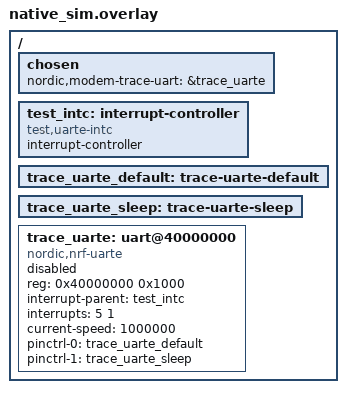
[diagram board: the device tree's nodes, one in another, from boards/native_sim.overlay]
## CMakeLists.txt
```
#
# Copyright (c) 2026 Nordic Semiconductor ASA
#
# SPDX-License-Identifier: LicenseRef-Nordic-5-Clause
#

cmake_minimum_required(VERSION 3.20.0)

find_package(Zephyr REQUIRED HINTS $ENV{ZEPHYR_BASE})
project(uart_nrfx)

zephyr_get(TEST_BOUNCE_BUF_SZ)
if(NOT DEFINED TEST_BOUNCE_BUF_SZ)
  set(TEST_BOUNCE_BUF_SZ 8)
endif()

# Stub headers for nrfx, pinctrl and DMM. They take precedence over the Zephyr headers.
target_include_directories(app BEFORE PRIVATE stubs)
target_include_directories(app PRIVATE src)
target_include_directories(app PRIVATE ${ZEPHYR_NRF_MODULE_DIR}/include/modem/)

# Provide compile-time definitions for configs expected by the backend
target_compile_definitions(app PRIVATE
  CONFIG_NRF_MODEM_LIB_TRACE_BACKEND_UART_NRFX_CHUNK_SZ=16
  CONFIG_NRF_MODEM_LIB_TRACE_BACKEND_UART_NRFX_BOUNCE_BUF_SZ=${TEST_BOUNCE_BUF_SZ}
  CONFIG_NRF_MODEM_LIB_TRACE_BACKEND_UART_NRFX_TX_TIMEOUT_MS=20
)

# Generate runner for the test
test_runner_generate(src/main.c)

target_sources(app PRIVATE
  src/main.c
  src/fake_nrfx_uarte.c
)

# Add the unit under test
target_sources(app PRIVATE
  ${ZEPHYR_NRF_MODULE_DIR}/lib/nrf_modem_lib/trace_backends/uart_nrfx/uart_nrfx.c)
```

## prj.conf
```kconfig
#
# Copyright (c) 2026 Nordic Semiconductor ASA
#
# SPDX-License-Identifier: LicenseRef-Nordic-5-Clause
#

CONFIG_UNITY=y
CONFIG_ASSERT=y
```

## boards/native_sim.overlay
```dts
/*
 * Copyright (c) 2026 Nordic Semiconductor ASA
 *
 * SPDX-License-Identifier: LicenseRef-Nordic-5-Clause
 */

/ {
	chosen {
		nordic,modem-trace-uart = &trace_uarte;
	};

	test_intc: interrupt-controller {
		compatible = "test,uarte-intc";
		interrupt-controller;
		#interrupt-cells = <2>;
	};

	trace_uarte_default: trace-uarte-default {};

	trace_uarte_sleep: trace-uarte-sleep {};

	trace_uarte: uart@40000000 {
		compatible = "nordic,nrf-uarte";
		reg = <0x40000000 0x1000>;
		interrupt-parent = <&test_intc>;
		interrupts = <5 1>;
		current-speed = <1000000>;
		pinctrl-0 = <&trace_uarte_default>;
		pinctrl-1 = <&trace_uarte_sleep>;
		pinctrl-names = "default", "sleep";
		status = "reserved";
	};
};
```

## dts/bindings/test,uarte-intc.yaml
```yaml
#
# Copyright (c) 2026 Nordic Semiconductor ASA
#
# SPDX-License-Identifier: LicenseRef-Nordic-5-Clause
#

description: Dummy interrupt controller for the UARTE trace backend unit test

compatible: "test,uarte-intc"

include: [base.yaml, interrupt-controller.yaml]

interrupt-cells:
  - irq
  - priority
```

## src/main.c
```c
/*
 * Copyright (c) 2026 Nordic Semiconductor ASA
 *
 * SPDX-License-Identifier: LicenseRef-Nordic-5-Clause
 */

#include <errno.h>
#include <string.h>
#include <unity.h>
#include <zephyr/kernel.h>
#include <zephyr/drivers/pinctrl.h>

#include <modem/trace_backend.h>

#include "fake_nrfx_uarte.h"

#define CHUNK_SZ      CONFIG_NRF_MODEM_LIB_TRACE_BACKEND_UART_NRFX_CHUNK_SZ
#define BOUNCE_BUF_SZ CONFIG_NRF_MODEM_LIB_TRACE_BACKEND_UART_NRFX_BOUNCE_BUF_SZ

#define MAX_CB_CALLS 32

extern int unity_main(void);

extern struct nrf_modem_lib_trace_backend trace_backend;

static uint8_t trace_data[128];

static struct {
	size_t calls;
	size_t lens[MAX_CB_CALLS];
	size_t total;
	/* Return fail_err on the given 1-based call. */
	size_t fail_at;
	int fail_err;
} processed;

static int processed_cb(size_t len)
{
	size_t call = ++processed.calls;

	if (call <= ARRAY_SIZE(processed.lens)) {
		processed.lens[call - 1] = len;
	}

	if (call == processed.fail_at) {
		return processed.fail_err;
	}

	processed.total += len;

	return 0;
}

static void backend_init(void)
{
	TEST_ASSERT_EQUAL(0, trace_backend.init(processed_cb));
}

/* The trace library deinitializes the backend after a write error. */
static void backend_reinit(void)
{
	TEST_ASSERT_EQUAL(0, trace_backend.deinit());
	backend_init();
}

static void reset_counters(void)
{
	memset(&processed, 0, sizeof(processed));
	fake_uarte.tx_calls = 0;
	fake_uarte.async_aborts = 0;
	fake_uarte.sync_aborts = 0;
	fake_uarte.events = 0;
	fake_uarte.sent_len = 0;
}

static void make_trace_data_inaccessible(void)
{
	fake_uarte.inaccessible = trace_data;
	fake_uarte.inaccessible_len = sizeof(trace_data);
}

/* Assert that a write of len bytes completed fully and in order, in chunks. */
static void assert_write_complete(int ret, size_t len, size_t chunk)
{
	TEST_ASSERT_EQUAL(len, ret);
	TEST_ASSERT_EQUAL(len, processed.total);
	TEST_ASSERT_EQUAL(DIV_ROUND_UP(len, chunk), processed.calls);
	for (size_t i = 0; i < processed.calls; i++) {
		TEST_ASSERT_EQUAL(MIN(chunk, len - i * chunk), processed.lens[i]);
	}
	TEST_ASSERT_EQUAL(len, fake_uarte.sent_len);
	TEST_ASSERT_EQUAL_MEMORY(trace_data, fake_uarte.sent, len);
}

/* Assert that a new write is not affected by leftovers of the previous one. */
static void assert_next_write_clean(void)
{
	int ret;

	fake_uarte.stalled = false;
	fake_uarte.abort_stuck = false;
	fake_uarte.complete_on_sync_abort = false;
	fake_uarte.complete_all = false;
	fake_uarte.tx_fail_at = 0;
	fake_uarte.link_cancel_count = 0;
	reset_counters();

	ret = trace_backend.write(trace_data, CHUNK_SZ + 4);
	assert_write_complete(ret, CHUNK_SZ + 4, CHUNK_SZ);
	TEST_ASSERT_EQUAL(2, fake_uarte.events);
}

void setUp(void)
{
	fake_uarte_reset();
	memset(&processed, 0, sizeof(processed));

	for (size_t i = 0; i < sizeof(trace_data); i++) {
		trace_data[i] = (uint8_t)(i * 7 + 3);
	}
}

void tearDown(void)
{
	(void)trace_backend.deinit();

	TEST_ASSERT_NULL_MESSAGE(fake_uarte.protocol_error, fake_uarte.protocol_error);
	TEST_ASSERT_FALSE(fake_uarte.overwrite_detected);
	TEST_ASSERT_LESS_OR_EQUAL(2, fake_uarte.max_queued);
}

void test_init_null_callback(void)
{
	TEST_ASSERT_EQUAL(-EFAULT, trace_backend.init(NULL));
	TEST_ASSERT_FALSE(fake_uarte.initialized);
}

void test_init_configures_uarte(void)
{
	backend_init();

	TEST_ASSERT_TRUE(fake_uarte.initialized);
	TEST_ASSERT_EQUAL(PINCTRL_STATE_DEFAULT, fake_uarte.pinctrl_state);
	/* 1 Mbaud from a 16 MHz clock: 2^12 * floor(2^20 / 16). */
	TEST_ASSERT_EQUAL_HEX32(0x10000000, fake_uarte.config.baudrate);
	TEST_ASSERT_EQUAL(NRF_UARTE_HWFC_DISABLED, fake_uarte.config.config.hwfc);
	TEST_ASSERT_TRUE(fake_uarte.config.skip_psel_cfg);
	TEST_ASSERT_TRUE(fake_uarte.config.skip_gpio_cfg);
	TEST_ASSERT_EQUAL(1, fake_uarte.config.interrupt_priority);

	/* Initializing again only updates the callback. */
	backend_init();
	TEST_ASSERT_EQUAL(1, fake_uarte.init_calls);
}

void test_init_pinctrl_error(void)
{
	fake_uarte.pinctrl_err = -EIO;

	TEST_ASSERT_EQUAL(-EIO, trace_backend.init(processed_cb));
	TEST_ASSERT_FALSE(fake_uarte.initialized);
	TEST_ASSERT_EQUAL(-EPERM, trace_backend.write(trace_data, 4));
}

void test_write_not_initialized(void)
{
	TEST_ASSERT_EQUAL(-EPERM, trace_backend.write(trace_data, 4));
	TEST_ASSERT_EQUAL(0, fake_uarte.tx_calls);
}

void test_deinit(void)
{
	backend_init();

	TEST_ASSERT_EQUAL(0, trace_backend.deinit());
	TEST_ASSERT_FALSE(fake_uarte.initialized);
	TEST_ASSERT_EQUAL(PINCTRL_STATE_SLEEP, fake_uarte.pinctrl_state);
	TEST_ASSERT_EQUAL(-EPERM, trace_backend.write(trace_data, 4));
}

void test_write_single_chunk(void)
{
	int ret;

	backend_init();

	ret = trace_backend.write(trace_data, 10);

	assert_write_complete(ret, 10, CHUNK_SZ);
	TEST_ASSERT_EQUAL(1, fake_uarte.tx_calls);
	TEST_ASSERT_EQUAL(0, fake_uarte.tx_log[0].flags);
	TEST_ASSERT_EQUAL_PTR(trace_data, fake_uarte.tx_log[0].buf);
}

void test_write_links_chunks(void)
{
	const size_t len = 3 * CHUNK_SZ + 5;
	int ret;

	backend_init();

	ret = trace_backend.write(trace_data, len);

	assert_write_complete(ret, len, CHUNK_SZ);
	TEST_ASSERT_EQUAL(4, fake_uarte.tx_calls);
	TEST_ASSERT_EQUAL(2, fake_uarte.max_queued);
	TEST_ASSERT_EQUAL(0, fake_uarte.tx_log[0].flags);
	for (size_t i = 1; i < fake_uarte.tx_calls; i++) {
		TEST_ASSERT_EQUAL(NRFX_UARTE_TX_LINK, fake_uarte.tx_log[i].flags);
		TEST_ASSERT_EQUAL_PTR(&trace_data[i * CHUNK_SZ], fake_uarte.tx_log[i].buf);
	}
	/* BAUDRATE is restored only when starting, not when linking. */
	TEST_ASSERT_EQUAL(1, fake_uarte.baudrate_restores);
}

void test_write_restores_baudrate_on_each_start(void)
{
	int ret;

	backend_init();
	TEST_ASSERT_EQUAL_HEX32(0, fake_uarte.baudrate);

	ret = trace_backend.write(trace_data, 4);
	assert_write_complete(ret, 4, CHUNK_SZ);

	reset_counters();
	ret = trace_backend.write(trace_data, 4);
	assert_write_complete(ret, 4, CHUNK_SZ);

	TEST_ASSERT_EQUAL(2, fake_uarte.baudrate_restores);
}

void test_write_link_after_transfers_done_starts_new(void)
{
	const size_t len = 5 * CHUNK_SZ;
	int ret;

	backend_init();
	fake_uarte.complete_all = true;

	/* Both transfers are done before the next one is linked, so the driver starts a new
	 * transfer which requires BAUDRATE to be restored.
	 */
	ret = trace_backend.write(trace_data, len);

	assert_write_complete(ret, len, CHUNK_SZ);
	TEST_ASSERT_EQUAL(0, fake_uarte.async_aborts);
	TEST_ASSERT_EQUAL(0, fake_uarte.sync_aborts);
	TEST_ASSERT_EQUAL(3, fake_uarte.baudrate_restores);
}

void test_write_link_canceled_is_fatal(void)
{
	backend_init();
	fake_uarte.link_cancel_count = 1;

	TEST_ASSERT_EQUAL(-ECANCELED, trace_backend.write(trace_data, 3 * CHUNK_SZ));
	TEST_ASSERT_EQUAL(2, fake_uarte.tx_calls);
	TEST_ASSERT_EQUAL(NRFX_UARTE_TX_LINK, fake_uarte.tx_log[1].flags);
	TEST_ASSERT_EQUAL(0, fake_uarte.async_aborts);
	TEST_ASSERT_EQUAL(1, fake_uarte.sync_aborts);
	TEST_ASSERT_EQUAL(0, processed.calls);

	backend_reinit();
	assert_next_write_clean();
}

void test_write_tx_error(void)
{
	backend_init();
	fake_uarte.tx_fail_at = 1;
	fake_uarte.tx_fail_err = -EIO;

	TEST_ASSERT_EQUAL(-EIO, trace_backend.write(trace_data, 2 * CHUNK_SZ));
	TEST_ASSERT_EQUAL(1, fake_uarte.tx_calls);
	TEST_ASSERT_EQUAL(0, processed.calls);
	TEST_ASSERT_EQUAL(0, fake_uarte.async_aborts);

	assert_next_write_clean();
}

void test_write_link_error_aborts_active_transfer(void)
{
	backend_init();
	fake_uarte.tx_fail_at = 2;
	fake_uarte.tx_fail_err = -EIO;

	TEST_ASSERT_EQUAL(-EIO, trace_backend.write(trace_data, 2 * CHUNK_SZ));
	TEST_ASSERT_EQUAL(2, fake_uarte.tx_calls);
	TEST_ASSERT_EQUAL(0, fake_uarte.async_aborts);
	TEST_ASSERT_EQUAL(1, fake_uarte.sync_aborts);
	TEST_ASSERT_EQUAL(0, fake_uarte.events);
	TEST_ASSERT_EQUAL(0, processed.calls);

	backend_reinit();
	assert_next_write_clean();
}

void test_write_processed_cb_error_aborts_linked_transfer(void)
{
	backend_init();
	processed.fail_at = 1;
	processed.fail_err = -ENOMEM;
	fake_uarte.abort_partial_len = 4;

	TEST_ASSERT_EQUAL(-ENOMEM, trace_backend.write(trace_data, 3 * CHUNK_SZ));

	/* The third chunk is never sent, and the aborted second chunk is not processed. */
	TEST_ASSERT_EQUAL(2, fake_uarte.tx_calls);
	TEST_ASSERT_EQUAL(1, fake_uarte.async_aborts);
	TEST_ASSERT_EQUAL(0, fake_uarte.sync_aborts);
	TEST_ASSERT_EQUAL(2, fake_uarte.events);
	TEST_ASSERT_EQUAL(1, processed.calls);
	TEST_ASSERT_EQUAL(CHUNK_SZ + 4, fake_uarte.sent_len);

	assert_next_write_clean();
}

void test_write_processed_cb_error_after_all_transfers_done(void)
{
	backend_init();
	processed.fail_at = 1;
	processed.fail_err = -ENOMEM;
	fake_uarte.complete_all = true;

	/* Both transfers are done when the first completion is handled, so the abort finds no
	 * active transfer and the second completion is already queued.
	 */
	TEST_ASSERT_EQUAL(-ENOMEM, trace_backend.write(trace_data, 2 * CHUNK_SZ));
	TEST_ASSERT_EQUAL(1, fake_uarte.async_aborts);
	TEST_ASSERT_EQUAL(0, fake_uarte.sync_aborts);
	TEST_ASSERT_EQUAL(2, fake_uarte.events);
	TEST_ASSERT_EQUAL(1, processed.calls);

	assert_next_write_clean();
}

void test_write_timeout_partial_abort(void)
{
	int ret;

	backend_init();
	fake_uarte.stalled = true;
	fake_uarte.abort_partial_len = 5;

	ret = trace_backend.write(trace_data, 2 * CHUNK_SZ);

	/* Bytes sent before the abort are processed, the linked transfer reports 0 bytes. */
	TEST_ASSERT_EQUAL(5, ret);
	TEST_ASSERT_EQUAL(1, processed.calls);
	TEST_ASSERT_EQUAL(5, processed.total);
	TEST_ASSERT_EQUAL(2, fake_uarte.events);
	TEST_ASSERT_EQUAL(1, fake_uarte.async_aborts);
	TEST_ASSERT_EQUAL(0, fake_uarte.sync_aborts);
	TEST_ASSERT_EQUAL(5, fake_uarte.sent_len);
	TEST_ASSERT_EQUAL_MEMORY(trace_data, fake_uarte.sent, 5);

	assert_next_write_clean();
}

void test_write_timeout_zero_byte_abort(void)
{
	backend_init();
	fake_uarte.stalled = true;
	fake_uarte.abort_partial_len = 0;

	TEST_ASSERT_EQUAL(-EAGAIN, trace_backend.write(trace_data, 2 * CHUNK_SZ));
	TEST_ASSERT_EQUAL(0, processed.calls);
	TEST_ASSERT_EQUAL(2, fake_uarte.events);
	TEST_ASSERT_EQUAL(1, fake_uarte.async_aborts);
	TEST_ASSERT_EQUAL(0, fake_uarte.sync_aborts);

	assert_next_write_clean();
}

void test_write_timeout_escalates_to_sync_abort(void)
{
	backend_init();
	fake_uarte.stalled = true;
	fake_uarte.abort_stuck = true;

	TEST_ASSERT_EQUAL(-ETIMEDOUT, trace_backend.write(trace_data, 2 * CHUNK_SZ));
	TEST_ASSERT_EQUAL(0, processed.calls);
	TEST_ASSERT_EQUAL(0, fake_uarte.events);
	TEST_ASSERT_EQUAL(1, fake_uarte.async_aborts);
	TEST_ASSERT_EQUAL(1, fake_uarte.sync_aborts);

	backend_reinit();
	assert_next_write_clean();
}

void test_write_sync_abort_discards_late_completion(void)
{
	backend_init();
	fake_uarte.stalled = true;
	fake_uarte.abort_stuck = true;
	fake_uarte.complete_on_sync_abort = true;

	/* A completion that races with the synchronous abort is discarded with the write. */
	TEST_ASSERT_EQUAL(-ETIMEDOUT, trace_backend.write(trace_data, 2 * CHUNK_SZ));
	TEST_ASSERT_EQUAL(0, processed.calls);
	TEST_ASSERT_EQUAL(1, fake_uarte.events);
	TEST_ASSERT_EQUAL(1, fake_uarte.sync_aborts);

	backend_reinit();
	assert_next_write_clean();
}

void test_suspend_resume(void)
{
	int ret;

	backend_init();

	TEST_ASSERT_EQUAL(0, trace_backend.suspend());
	TEST_ASSERT_EQUAL(PINCTRL_STATE_SLEEP, fake_uarte.pinctrl_state);
	TEST_ASSERT_EQUAL(-EPERM, trace_backend.write(trace_data, 4));
	TEST_ASSERT_EQUAL(0, fake_uarte.tx_calls);

	TEST_ASSERT_EQUAL(0, trace_backend.resume());
	TEST_ASSERT_EQUAL(PINCTRL_STATE_DEFAULT, fake_uarte.pinctrl_state);

	ret = trace_backend.write(trace_data, 4);
	assert_write_complete(ret, 4, CHUNK_SZ);
}

void test_suspend_pinctrl_error(void)
{
	int ret;

	backend_init();
	fake_uarte.pinctrl_err = -EIO;

	TEST_ASSERT_EQUAL(-EIO, trace_backend.suspend());

	/* The backend is not suspended. */
	fake_uarte.pinctrl_err = 0;
	ret = trace_backend.write(trace_data, 4);
	assert_write_complete(ret, 4, CHUNK_SZ);
}

void test_write_dma_accessible_data_sent_in_place(void)
{
#if BOUNCE_BUF_SZ > 0
	int ret;

	backend_init();

	ret = trace_backend.write(trace_data, 2 * CHUNK_SZ);

	assert_write_complete(ret, 2 * CHUNK_SZ, CHUNK_SZ);
	TEST_ASSERT_EQUAL_PTR(&trace_data[0], fake_uarte.tx_log[0].buf);
	TEST_ASSERT_EQUAL_PTR(&trace_data[CHUNK_SZ], fake_uarte.tx_log[1].buf);
#else
	TEST_IGNORE_MESSAGE("Bounce buffers are disabled");
#endif
}

void test_write_bounce_buffers_alternate(void)
{
#if BOUNCE_BUF_SZ > 0
	const size_t len = 5 * BOUNCE_BUF_SZ;
	int ret;

	backend_init();
	make_trace_data_inaccessible();

	ret = trace_backend.write(trace_data, len);

	assert_write_complete(ret, len, BOUNCE_BUF_SZ);
	TEST_ASSERT_EQUAL(5, fake_uarte.tx_calls);
	TEST_ASSERT_EQUAL(2, fake_uarte.max_queued);
	for (size_t i = 0; i < fake_uarte.tx_calls; i++) {
		TEST_ASSERT_EQUAL(BOUNCE_BUF_SZ, fake_uarte.tx_log[i].len);
		TEST_ASSERT_TRUE(nrf_dma_accessible_check(NULL, fake_uarte.tx_log[i].buf));
	}
	/* Consecutive transfers, which may be in flight at the same time, use different
	 * bounce buffers.
	 */
	for (size_t i = 1; i < fake_uarte.tx_calls; i++) {
		TEST_ASSERT_TRUE(fake_uarte.tx_log[i - 1].buf != fake_uarte.tx_log[i].buf);
	}
	TEST_ASSERT_EQUAL_PTR(fake_uarte.tx_log[0].buf, fake_uarte.tx_log[2].buf);
#else
	TEST_IGNORE_MESSAGE("Bounce buffers are disabled");
#endif
}

void test_write_bounce_buffers_after_abort(void)
{
#if BOUNCE_BUF_SZ > 0
	int ret;

	backend_init();
	make_trace_data_inaccessible();
	fake_uarte.stalled = true;
	fake_uarte.abort_stuck = true;

	TEST_ASSERT_EQUAL(-ETIMEDOUT, trace_backend.write(trace_data, 2 * BOUNCE_BUF_SZ));
	TEST_ASSERT_EQUAL(1, fake_uarte.sync_aborts);

	fake_uarte.stalled = false;
	fake_uarte.abort_stuck = false;
	backend_reinit();
	reset_counters();

	ret = trace_backend.write(trace_data, 3 * BOUNCE_BUF_SZ);
	assert_write_complete(ret, 3 * BOUNCE_BUF_SZ, BOUNCE_BUF_SZ);
#else
	TEST_IGNORE_MESSAGE("Bounce buffers are disabled");
#endif
}

void test_write_not_dma_accessible(void)
{
#if BOUNCE_BUF_SZ == 0
	backend_init();
	make_trace_data_inaccessible();

	TEST_ASSERT_EQUAL(-EFAULT, trace_backend.write(trace_data, CHUNK_SZ));
	TEST_ASSERT_EQUAL(0, fake_uarte.tx_calls);
	TEST_ASSERT_EQUAL(0, processed.calls);
#else
	TEST_IGNORE_MESSAGE("Bounce buffers are enabled");
#endif
}

int main(void)
{
	(void)unity_main();
	return 0;
}
```

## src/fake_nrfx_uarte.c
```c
/*
 * Copyright (c) 2026 Nordic Semiconductor ASA
 *
 * SPDX-License-Identifier: LicenseRef-Nordic-5-Clause
 */

#include <errno.h>
#include <string.h>
#include <zephyr/kernel.h>
#include <zephyr/drivers/pinctrl.h>

#include "fake_nrfx_uarte.h"

#define MAX_QUEUED 2

/* A transfer owned by the fake hardware, with a copy of the data taken when it was started. */
struct xfer {
	const uint8_t *buf;
	size_t len;
	uint8_t snapshot[CONFIG_NRF_MODEM_LIB_TRACE_BACKEND_UART_NRFX_CHUNK_SZ];
};

struct fake_uarte fake_uarte;

static struct xfer queue[MAX_QUEUED];
static size_t queued;
static bool abort_requested;
static bool enabled;
/* The driver flags left behind by a synchronous abort, which only uninit clears. */
static bool stale_state;
static nrfx_uarte_event_handler_t evt_handler;
static void *evt_ctx;

static void hw_tick(struct k_timer *timer);
static K_TIMER_DEFINE(hw_timer, hw_tick, NULL);

static void protocol_error(const char *msg)
{
	if (!fake_uarte.protocol_error) {
		fake_uarte.protocol_error = msg;
	}
}

static void check_overwrite(const struct xfer *x)
{
	if (memcmp(x->buf, x->snapshot, x->len) != 0) {
		fake_uarte.overwrite_detected = true;
	}
}

/* The driver disables the UARTE when TX stops. */
static void hw_disable(void)
{
	enabled = false;
	fake_uarte.baudrate = 0;
}

static void enqueue(const uint8_t *buf, size_t len)
{
	struct xfer *x = &queue[queued++];

	x->buf = buf;
	x->len = len;
	memcpy(x->snapshot, buf, len);
	fake_uarte.max_queued = MAX(fake_uarte.max_queued, queued);
}

static void complete_head(size_t len, bool aborted)
{
	struct xfer x = queue[0];
	nrfx_uarte_event_t evt = {
		.type = NRFX_UARTE_EVT_TX_DONE,
		.data.tx.p_buffer = x.buf,
		.data.tx.length = len,
		.data.tx.flags = aborted ? NRFX_UARTE_TX_DONE_ABORTED : 0,
	};

	check_overwrite(&x);

	if (fake_uarte.sent_len + len <= sizeof(fake_uarte.sent)) {
		memcpy(&fake_uarte.sent[fake_uarte.sent_len], x.buf, len);
		fake_uarte.sent_len += len;
	} else {
		protocol_error("sent log overflow");
	}

	queue[0] = queue[1];
	queued--;
	fake_uarte.events++;

	if (queued == 0) {
		hw_disable();
	}

	evt_handler(&evt, evt_ctx);
}

static void hw_tick(struct k_timer *timer)
{
	ARG_UNUSED(timer);

	if (abort_requested) {
		if (fake_uarte.abort_stuck) {
			return;
		}

		abort_requested = false;

		/* The active transfer reports what was sent, a linked one reports 0 bytes. */
		if (queued > 0) {
			complete_head(MIN(fake_uarte.abort_partial_len, queue[0].len), true);
		}
		while (queued > 0) {
			complete_head(0, true);
		}
		return;
	}

	if (fake_uarte.stalled) {
		return;
	}

	do {
		if (queued > 0) {
			complete_head(queue[0].len, false);
		}
	} while (fake_uarte.complete_all && queued > 0);
}

void fake_uarte_reset(void)
{
	k_timer_stop(&hw_timer);
	memset(&fake_uarte, 0, sizeof(fake_uarte));
	queued = 0;
	abort_requested = false;
	enabled = false;
	stale_state = false;
	evt_handler = NULL;
	evt_ctx = NULL;
}

int nrfx_uarte_init(nrfx_uarte_t *p_instance, nrfx_uarte_config_t const *p_config,
		    nrfx_uarte_event_handler_t event_handler)
{
	ARG_UNUSED(p_instance);

	fake_uarte.init_calls++;

	if (fake_uarte.initialized) {
		return -EALREADY;
	}

	if (event_handler == NULL) {
		protocol_error("blocking mode is not supported");
		return -EINVAL;
	}

	fake_uarte.config = *p_config;
	fake_uarte.initialized = true;
	evt_handler = event_handler;
	evt_ctx = p_config->p_context;
	queued = 0;
	abort_requested = false;
	stale_state = false;
	/* BAUDRATE is written while the UARTE is disabled, so it is lost. */
	hw_disable();

	k_timer_start(&hw_timer, K_MSEC(1), K_MSEC(1));

	return 0;
}

void nrfx_uarte_uninit(nrfx_uarte_t *p_instance)
{
	ARG_UNUSED(p_instance);

	k_timer_stop(&hw_timer);
	fake_uarte.initialized = false;
	queued = 0;
	abort_requested = false;
	stale_state = false;
	hw_disable();
}

int nrfx_uarte_tx(nrfx_uarte_t *p_instance, uint8_t const *p_data, size_t length, uint32_t flags)
{
	struct fake_uarte_tx_call *call = NULL;
	size_t idx = fake_uarte.tx_calls++;
	int ret = 0;

	ARG_UNUSED(p_instance);

	if (idx < ARRAY_SIZE(fake_uarte.tx_log)) {
		call = &fake_uarte.tx_log[idx];
		call->buf = p_data;
		call->len = length;
		call->flags = flags;
	} else {
		protocol_error("tx log overflow");
	}

	if (!fake_uarte.initialized) {
		protocol_error("tx while not initialized");
		ret = -EPERM;
	} else if (stale_state) {
		protocol_error("tx after synchronous abort without uninit");
		ret = -EBUSY;
	} else if (length == 0 || length > sizeof(queue[0].snapshot)) {
		protocol_error("invalid tx length");
		ret = -EINVAL;
	} else if (!nrf_dma_accessible_check(NULL, p_data) ||
		   !nrf_dma_accessible_check(NULL, p_data + length - 1)) {
		protocol_error("tx from memory that is not DMA accessible");
		ret = -EACCES;
	} else if (abort_requested) {
		protocol_error("tx while abort is pending");
		ret = -EBUSY;
	} else if (fake_uarte.tx_fail_at == idx + 1) {
		ret = fake_uarte.tx_fail_err;
	} else if ((flags & NRFX_UARTE_TX_LINK) && queued == 1 &&
		   fake_uarte.link_cancel_count > 0) {
		/* The driver keeps the transfer linked even though it reports a failure. */
		fake_uarte.link_cancel_count--;
		enqueue(p_data, length);
		ret = -ECANCELED;
	} else if (queued == MAX_QUEUED) {
		protocol_error("more than two transfers in flight");
		ret = -EBUSY;
	} else if (queued > 0 && !(flags & NRFX_UARTE_TX_LINK)) {
		protocol_error("tx without link while busy");
		ret = -EBUSY;
	} else {
		if (queued == 0 && fake_uarte.baudrate == 0) {
			protocol_error("tx started without restoring BAUDRATE");
		}
		enqueue(p_data, length);
	}

	if (call) {
		call->ret = ret;
	}

	return ret;
}

int nrfx_uarte_tx_abort(nrfx_uarte_t *p_instance, bool sync)
{
	ARG_UNUSED(p_instance);

	if (sync) {
		fake_uarte.sync_aborts++;
		if (fake_uarte.complete_on_sync_abort && queued > 0) {
			complete_head(queue[0].len, false);
		}
		if (queued == 0) {
			return -EINPROGRESS;
		}
		for (size_t i = 0; i < queued; i++) {
			check_overwrite(&queue[i]);
		}
		/* Only the active transfer is cleared, the aborted and linked flags remain. */
		stale_state = true;
		queued = 0;
		abort_requested = false;
		hw_disable();
		return 0;
	}

	fake_uarte.async_aborts++;

	if (queued == 0) {
		return -EINPROGRESS;
	}

	abort_requested = true;

	return 0;
}

void nrfx_uarte_irq_handler(const void *p_instance)
{
	ARG_UNUSED(p_instance);
}

bool nrfx_uarte_tx_in_progress(nrfx_uarte_t const *p_instance)
{
	ARG_UNUSED(p_instance);

	return queued > 0;
}

void nrf_uarte_enable(NRF_UARTE_Type *p_reg)
{
	ARG_UNUSED(p_reg);

	enabled = true;
}

void nrf_uarte_baudrate_set(NRF_UARTE_Type *p_reg, nrf_uarte_baudrate_t baudrate)
{
	ARG_UNUSED(p_reg);

	if (enabled) {
		fake_uarte.baudrate = baudrate;
		fake_uarte.baudrate_restores++;
	}
}

bool nrf_dma_accessible_check(void const *p_reg, void const *p_object)
{
	const uint8_t *addr = p_object;

	ARG_UNUSED(p_reg);

	return !(fake_uarte.inaccessible && addr >= fake_uarte.inaccessible &&
		 addr < fake_uarte.inaccessible + fake_uarte.inaccessible_len);
}

int pinctrl_apply_state(const struct pinctrl_dev_config *config, uint8_t id)
{
	ARG_UNUSED(config);

	fake_uarte.pinctrl_calls++;

	if (fake_uarte.pinctrl_err) {
		return fake_uarte.pinctrl_err;
	}

	fake_uarte.pinctrl_state = id;

	return 0;
}
```

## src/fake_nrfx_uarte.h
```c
/*
 * Copyright (c) 2026 Nordic Semiconductor ASA
 *
 * SPDX-License-Identifier: LicenseRef-Nordic-5-Clause
 */

#ifndef FAKE_NRFX_UARTE_H__
#define FAKE_NRFX_UARTE_H__

#include <stdbool.h>
#include <stddef.h>
#include <stdint.h>
#include <nrfx_uarte.h>

#define FAKE_UARTE_TX_LOG_LEN 32
#define FAKE_UARTE_SENT_LEN   256

struct fake_uarte_tx_call {
	const uint8_t *buf;
	size_t len;
	uint32_t flags;
	int ret;
};

/* The fake UARTE completes one transfer per millisecond tick, unless configured otherwise. */
struct fake_uarte {
	/* Behavior controls, set by the test. */

	/* Transfers do not complete on their own. */
	bool stalled;
	/* Asynchronous aborts never complete. */
	bool abort_stuck;
	/* The active transfer completes right before a synchronous abort, as if the interrupt
	 * fired just before the abort was requested.
	 */
	bool complete_on_sync_abort;
	/* Number of bytes reported as sent for the active transfer when it is aborted. */
	size_t abort_partial_len;
	/* Complete all queued transfers on each tick instead of one. */
	bool complete_all;
	/* Fail the next linked transfers with -ECANCELED, as when TXSTARTED is not seen in time.
	 * Like the real driver, the transfer stays linked and is sent after the active one.
	 */
	int link_cancel_count;
	/* Fail the transfer request with the given 1-based call index. */
	size_t tx_fail_at;
	int tx_fail_err;
	/* Memory that is not accessible by EasyDMA. */
	const uint8_t *inaccessible;
	size_t inaccessible_len;
	/* Error returned by pinctrl_apply_state(). */
	int pinctrl_err;

	/* Observations. */
	bool initialized;
	size_t init_calls;
	nrfx_uarte_config_t config;
	struct fake_uarte_tx_call tx_log[FAKE_UARTE_TX_LOG_LEN];
	size_t tx_calls;
	size_t max_queued;
	size_t async_aborts;
	size_t sync_aborts;
	/* BAUDRATE register, which is lost while the UARTE is disabled, as on UARTE120. */
	uint32_t baudrate;
	size_t baudrate_restores;
	size_t events;
	uint8_t sent[FAKE_UARTE_SENT_LEN];
	size_t sent_len;
	bool overwrite_detected;
	const char *protocol_error;
	uint8_t pinctrl_state;
	size_t pinctrl_calls;
};

extern struct fake_uarte fake_uarte;

void fake_uarte_reset(void);

#endif /* FAKE_NRFX_UARTE_H__ */
```
